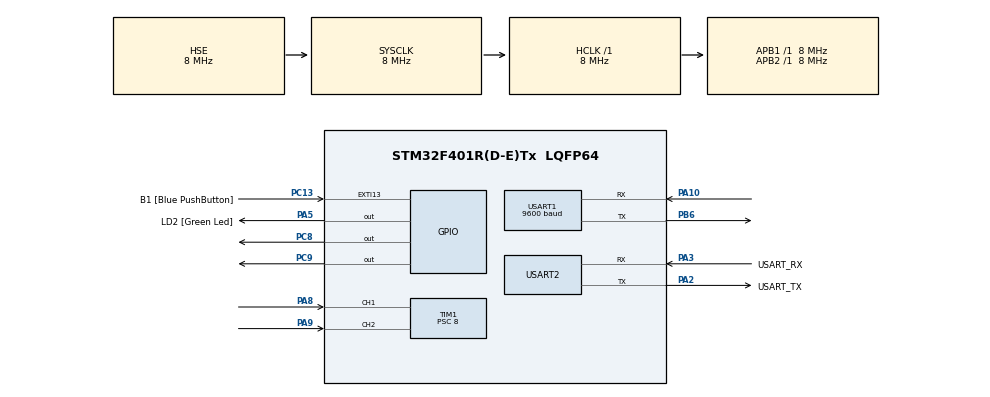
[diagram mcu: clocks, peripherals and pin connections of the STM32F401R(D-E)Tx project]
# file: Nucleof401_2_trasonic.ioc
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Mcu.Family=STM32F4
Mcu.Name=STM32F401R(D-E)Tx
Mcu.Package=LQFP64
NVIC.PriorityGroup=NVIC_PRIORITYGROUP_0
NVIC.TIM1_CC_IRQn=true\:0\:0\:false\:false\:true\:true\:true\:true
PA10.Mode=Asynchronous
PA10.Signal=USART1_RX
PA13.GPIO_Label=TMS
PA13.Mode=Serial_Wire
PA13.Signal=SYS_JTMS-SWDIO
PA14.GPIO_Label=TCK
PA14.Mode=Serial_Wire
PA14.Signal=SYS_JTCK-SWCLK
PA2.GPIO_Label=USART_TX
PA2.GPIO_Mode=GPIO_MODE_AF_PP
PA2.GPIO_PuPd=GPIO_NOPULL
PA2.GPIO_Speed=GPIO_SPEED_FREQ_LOW
PA2.Mode=Asynchronous
PA2.Signal=USART2_TX
PA3.GPIO_Label=USART_RX
PA3.GPIO_Mode=GPIO_MODE_AF_PP
PA3.GPIO_PuPd=GPIO_NOPULL
PA3.GPIO_Speed=GPIO_SPEED_FREQ_LOW
PA3.Mode=Asynchronous
PA3.Signal=USART2_RX
PA5.GPIO_Label=LD2 [Green Led]
PA5.GPIO_Mode=GPIO_MODE_OUTPUT_PP
PA5.GPIO_PuPd=GPIO_NOPULL
PA5.GPIO_Speed=GPIO_SPEED_FREQ_LOW
PA5.Signal=GPIO_Output
PA8.Signal=S_TIM1_CH1
PA9.Signal=S_TIM1_CH2
PB3.GPIO_Label=SWO
PB3.Signal=SYS_JTDO-SWO
PB6.Mode=Asynchronous
PB6.Signal=USART1_TX
PC13-ANTI_TAMP.GPIO_Label=B1 [Blue PushButton]
PC13-ANTI_TAMP.GPIO_ModeDefaultEXTI=GPIO_MODE_IT_FALLING
PC13-ANTI_TAMP.GPIO_PuPd=GPIO_NOPULL
PC13-ANTI_TAMP.Signal=GPXTI13
PC14-OSC32_IN.Mode=LSE-External-Oscillator
PC14-OSC32_IN.Signal=RCC_OSC32_IN
PC15-OSC32_OUT.Mode=LSE-External-Oscillator
PC15-OSC32_OUT.Signal=RCC_OSC32_OUT
PC8.Signal=GPIO_Output
PC9.Signal=GPIO_Output
PH0\ -\ OSC_IN.Mode=HSE-External-Clock-Source
PH0\ -\ OSC_IN.Signal=RCC_OSC_IN
PH1\ -\ OSC_OUT.Mode=HSE-External-Clock-Source
PH1\ -\ OSC_OUT.Signal=RCC_OSC_OUT
ProjectManager.HeapSize=0x200
ProjectManager.StackSize=0x400
ProjectManager.TargetToolchain=STM32CubeIDE
RCC.48MHZClocksFreq_Value=24000000
RCC.AHBFreq_Value=8000000
RCC.APB1Freq_Value=8000000
RCC.APB1TimFreq_Value=8000000
RCC.APB2Freq_Value=8000000
RCC.APB2TimFreq_Value=8000000
RCC.CortexFreq_Value=8000000
RCC.HCLKFreq_Value=8000000
RCC.HSE_VALUE=8000000
RCC.HSI_VALUE=16000000
RCC.LSE_VALUE=32.77
RCC.PLLN=336
RCC.PLLP=RCC_PLLP_DIV4
RCC.PLLQ=7
RCC.PLLSourceVirtual=RCC_PLLSOURCE_HSE
RCC.SYSCLKFreq_VALUE=8000000
RCC.SYSCLKSource=RCC_SYSCLKSOURCE_HSE
RCC.VCOOutputFreq_Value=168000000
SH.S_TIM1_CH1.0=TIM1_CH1,Input_Capture1_from_TI1
SH.S_TIM1_CH2.0=TIM1_CH2,Input_Capture2_from_TI2
TIM1.Channel-Input_Capture1_from_TI1=TIM_CHANNEL_1
TIM1.Channel-Input_Capture2_from_TI2=TIM_CHANNEL_2
TIM1.Period=0xffff -1
TIM1.Prescaler=8
USART1.BaudRate=9600
USART1.VirtualMode=VM_ASYNC
USART2.VirtualMode=VM_ASYNC
board=NUCLEO-F401RE

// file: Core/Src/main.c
/* USER CODE BEGIN Header */
/**
  ******************************************************************************
  * @file           : main.c
  * @brief          : Main program body
  ******************************************************************************
  * @attention
  *
  * Copyright (c) 2024 STMicroelectronics.
  * All rights reserved.
  *
  * This software is licensed under terms that can be found in the LICENSE file
  * in the root directory of this software component.
  * If no LICENSE file comes with this software, it is provided AS-IS.
  *
  ******************************************************************************
  */
/* USER CODE END Header */
#include "main.h"
#include "tim.h"
#include "usart.h"
#include "gpio.h"

/* USER CODE BEGIN Includes */

#include "Ultrasonic.h"

/* USER CODE END Includes */

void SystemClock_Config(void);

/* USER CODE BEGIN 0 */

uint16_t Catched_Dis = 0 ;

/* USER CODE END 0 */

int main(void)
{

  /* MCU Configuration--------------------------------------------------------*/

  /* Reset of all peripherals, Initializes the Flash interface and the Systick. */
  HAL_Init();

  /* Configure the system clock */
  SystemClock_Config();

  /* Initialize all configured peripherals */
  MX_GPIO_Init();
  MX_USART2_UART_Init();
  MX_TIM1_Init();
  MX_USART1_UART_Init();
  /* USER CODE BEGIN 2 */

  /*  ⚠�?used to set ICU interrupt   */
  HAL_TIM_IC_Start_IT(&htim1, TIM_CHANNEL_1);
  HAL_TIM_IC_Start_IT(&htim1, TIM_CHANNEL_2);

  /* USER CODE END 2 */

  /* Infinite loop */
  /* USER CODE BEGIN WHILE */
  while (1)
  {

    Catched_Dis = Ultrasonic_Distance();
    /* USER CODE END WHILE */

  }
}

void SystemClock_Config(void)
{
  RCC_OscInitTypeDef RCC_OscInitStruct = {0};
  RCC_ClkInitTypeDef RCC_ClkInitStruct = {0};

  /** Configure the main internal regulator output voltage
  */
  __HAL_RCC_PWR_CLK_ENABLE();
  __HAL_PWR_VOLTAGESCALING_CONFIG(PWR_REGULATOR_VOLTAGE_SCALE2);

  /** Initializes the RCC Oscillators according to the specified parameters
  * in the RCC_OscInitTypeDef structure.
  */
  RCC_OscInitStruct.OscillatorType = RCC_OSCILLATORTYPE_HSE;
  RCC_OscInitStruct.HSEState = RCC_HSE_BYPASS;
  RCC_OscInitStruct.PLL.PLLState = RCC_PLL_NONE;
  if (HAL_RCC_OscConfig(&RCC_OscInitStruct) != HAL_OK)
  {
    Error_Handler();
  }

  /** Initializes the CPU, AHB and APB buses clocks
  */
  RCC_ClkInitStruct.ClockType = RCC_CLOCKTYPE_HCLK|RCC_CLOCKTYPE_SYSCLK
                              |RCC_CLOCKTYPE_PCLK1|RCC_CLOCKTYPE_PCLK2;
  RCC_ClkInitStruct.SYSCLKSource = RCC_SYSCLKSOURCE_HSE;
  RCC_ClkInitStruct.AHBCLKDivider = RCC_SYSCLK_DIV1;
  RCC_ClkInitStruct.APB1CLKDivider = RCC_HCLK_DIV1;
  RCC_ClkInitStruct.APB2CLKDivider = RCC_HCLK_DIV1;

  if (HAL_RCC_ClockConfig(&RCC_ClkInitStruct, FLASH_LATENCY_0) != HAL_OK)
  {
    Error_Handler();
  }
}

void Error_Handler(void)
{
  __disable_irq();
  while (1)
  {
  }
}
